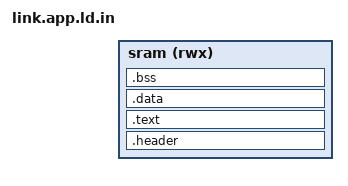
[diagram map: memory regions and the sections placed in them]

MEMORY 
{
  sram  (rwx) : ORIGIN = @APP_START@, LENGTH = @APP_SIZE@
}

SECTIONS
{
  .header :
  {
      . = ALIGN(4);
      hader_start = .;
      LONG(@HEADER_W1@);
      LONG(@HEADER_W2@);
      LONG(@FLASH_TEXT_START@);             /* test_start (in flash) */
      LONG(ABSOLUTE(hader_start));          /* text_dest (Where to load) */
      LONG(ABSOLUTE(_load_size))            /* size to load */
      LONG(ABSOLUTE(_bss_start))            /* start of bss_clear */
      LONG(_bss_len)                        /* len to clear */
      LONG(ABSOLUTE(main))                  /* address of entry point */
  } > sram

  .text :
  {
      . = ALIGN(4);
      PROVIDE(_text_start = .);
      *(.text .text.*)                      /* remaining code */
      *(.rodata)                            /* read-only data (constants) */
      *(.rodata*)
      *(.rdata*)
      . = ALIGN(4);
      PROVIDE(_text_end = .);
  } > sram
  
  .data : 
  {   
    . = ALIGN(4);
    PROVIDE(_data_start = .);
    
    *(.got.plt) *(.got)
    *(.shdata)
    *(.data .data.* .gnu.linkonce.d.*)
    . = ALIGN(16);
    . = ALIGN (8);
    *(.ram)
    *(.eh_frame)
    . = ALIGN (8);
    PROVIDE(_edata = .);
    PROVIDE(_data_end = .);
    PROVIDE(_load_size = . - hader_start);
  } > sram
   
  .bss : 
  {
    . = ALIGN(4);
    PROVIDE(_bss_start = .);
    *(.bss*)
    *(COMMON)
    . = ALIGN(4);
    PROVIDE(_bss_end = .);
    PROVIDE(_bss_len = . - _bss_start);
    . += 8;

    __heap_start__ = .;
    end = __heap_start__;
    _end = end;
    __end = end;
    KEEP(*(.heap))
    __heap_end__ = .;
    __HeapLimit = __heap_end__;
  } > sram
}
